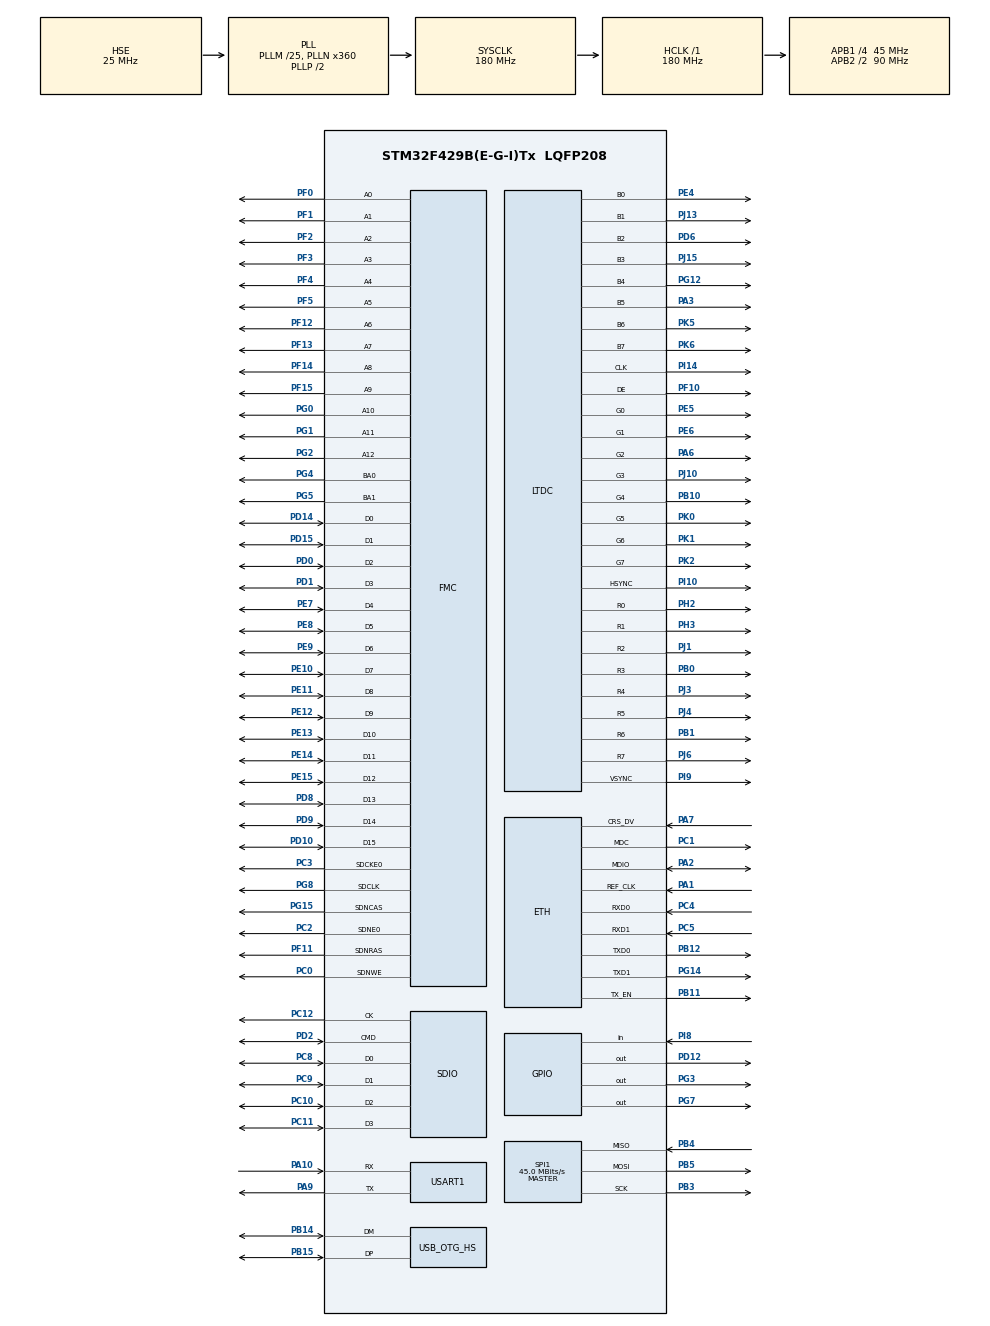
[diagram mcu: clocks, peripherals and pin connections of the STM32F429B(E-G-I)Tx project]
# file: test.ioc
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ETH.MediaInterface=ETH_MEDIA_INTERFACE_RMII
Mcu.Family=STM32F4
Mcu.Name=STM32F429B(E-G-I)Tx
Mcu.Package=LQFP208
NVIC.ETH_IRQn=true\:0\:0\:false\:false\:true
NVIC.PriorityGroup=NVIC_PRIORITYGROUP_2
NVIC.USART1_IRQn=true\:2\:1\:true\:true\:true\:1
PA1.Mode=RMII
PA1.Signal=ETH_REF_CLK
PA10.Mode=Asynchronous
PA10.Signal=USART1_RX
PA2.Mode=RMII
PA2.Signal=ETH_MDIO
PA3.Mode=RGB888
PA3.Signal=LTDC_B5
PA6.Mode=RGB888
PA6.Signal=LTDC_G2
PA7.Mode=RMII
PA7.Signal=ETH_CRS_DV
PA9.Mode=Asynchronous
PA9.Signal=USART1_TX
PB0.Mode=RGB888
PB0.Signal=LTDC_R3
PB1.Mode=RGB888
PB1.Signal=LTDC_R6
PB10.Mode=RGB888
PB10.Signal=LTDC_G4
PB11.Mode=RMII
PB11.Signal=ETH_TX_EN
PB12.Mode=RMII
PB12.Signal=ETH_TXD0
PB14.Mode=Device_Only_FS
PB14.Signal=USB_OTG_HS_DM
PB15.Mode=Device_Only_FS
PB15.Signal=USB_OTG_HS_DP
PB3.Mode=Full_Duplex_Master
PB3.Signal=SPI1_SCK
PB4.Mode=Full_Duplex_Master
PB4.Signal=SPI1_MISO
PB5.Mode=Full_Duplex_Master
PB5.Signal=SPI1_MOSI
PC0.Signal=FMC_SDNWE
PC1.Mode=RMII
PC1.Signal=ETH_MDC
PC10.Mode=SD_4_bits_Wide_bus
PC10.Signal=SDIO_D2
PC11.Mode=SD_4_bits_Wide_bus
PC11.Signal=SDIO_D3
PC12.Mode=SD_4_bits_Wide_bus
PC12.Signal=SDIO_CK
PC2.Mode=SdramChipSelect1_1
PC2.Signal=FMC_SDNE0
PC3.Mode=SdramChipSelect1_1
PC3.Signal=FMC_SDCKE0
PC4.Mode=RMII
PC4.Signal=ETH_RXD0
PC5.Mode=RMII
PC5.Signal=ETH_RXD1
PC8.Mode=SD_4_bits_Wide_bus
PC8.Signal=SDIO_D0
PC9.Mode=SD_4_bits_Wide_bus
PC9.Signal=SDIO_D1
PD0.Signal=FMC_D2_DA2
PD1.Signal=FMC_D3_DA3
PD10.Signal=FMC_D15_DA15
PD12.Signal=GPIO_Output
PD14.Signal=FMC_D0_DA0
PD15.Signal=FMC_D1_DA1
PD2.Mode=SD_4_bits_Wide_bus
PD2.Signal=SDIO_CMD
PD6.Mode=RGB888
PD6.Signal=LTDC_B2
PD8.Signal=FMC_D13_DA13
PD9.Signal=FMC_D14_DA14
PE10.Signal=FMC_D7_DA7
PE11.Signal=FMC_D8_DA8
PE12.Signal=FMC_D9_DA9
PE13.Signal=FMC_D10_DA10
PE14.Signal=FMC_D11_DA11
PE15.Signal=FMC_D12_DA12
PE4.Mode=RGB888
PE4.Signal=LTDC_B0
PE5.Mode=RGB888
PE5.Signal=LTDC_G0
PE6.Mode=RGB888
PE6.Signal=LTDC_G1
PE7.Signal=FMC_D4_DA4
PE8.Signal=FMC_D5_DA5
PE9.Signal=FMC_D6_DA6
PF0.Signal=FMC_A0
PF1.Signal=FMC_A1
PF10.Mode=RGB888
PF10.Signal=LTDC_DE
PF11.Signal=FMC_SDNRAS
PF12.Signal=FMC_A6
PF13.Signal=FMC_A7
PF14.Signal=FMC_A8
PF15.Signal=FMC_A9
PF2.Signal=FMC_A2
PF3.Signal=FMC_A3
PF4.Signal=FMC_A4
PF5.Signal=FMC_A5
PG0.Signal=FMC_A10
PG1.Signal=FMC_A11
PG12.Mode=RGB888
PG12.Signal=LTDC_B4
PG14.Mode=RMII
PG14.Signal=ETH_TXD1
PG15.Signal=FMC_SDNCAS
PG2.Signal=FMC_A12
PG3.Signal=GPIO_Output
PG4.Signal=FMC_A14_BA0
PG5.Signal=FMC_A15_BA1
PG7.Signal=GPIO_Output
PG8.Signal=FMC_SDCLK
PH0/OSC_IN.Mode=HSE-External-Oscillator
PH0/OSC_IN.Signal=RCC_OSC_IN
PH1/OSC_OUT.Mode=HSE-External-Oscillator
PH1/OSC_OUT.Signal=RCC_OSC_OUT
PH2.Mode=RGB888
PH2.Signal=LTDC_R0
PH3.Mode=RGB888
PH3.Signal=LTDC_R1
PI10.Mode=RGB888
PI10.Signal=LTDC_HSYNC
PI14.Mode=RGB888
PI14.Signal=LTDC_CLK
PI8.Signal=GPIO_Input
PI9.Mode=RGB888
PI9.Signal=LTDC_VSYNC
PJ1.Mode=RGB888
PJ1.Signal=LTDC_R2
PJ10.Mode=RGB888
PJ10.Signal=LTDC_G3
PJ13.Mode=RGB888
PJ13.Signal=LTDC_B1
PJ15.Mode=RGB888
PJ15.Signal=LTDC_B3
PJ3.Mode=RGB888
PJ3.Signal=LTDC_R4
PJ4.Mode=RGB888
PJ4.Signal=LTDC_R5
PJ6.Mode=RGB888
PJ6.Signal=LTDC_R7
PK0.Mode=RGB888
PK0.Signal=LTDC_G5
PK1.Mode=RGB888
PK1.Signal=LTDC_G6
PK2.Mode=RGB888
PK2.Signal=LTDC_G7
PK5.Mode=RGB888
PK5.Signal=LTDC_B6
PK6.Mode=RGB888
PK6.Signal=LTDC_B7
ProjectManager.HeapSize=0x200
ProjectManager.StackSize=0x400
ProjectManager.TargetToolchain=MDK-ARM V5
RCC.48MHZClocksFreq_Value=90000000
RCC.AHBFreq_Value=180000000
RCC.APB1CLKDivider=RCC_HCLK_DIV4
RCC.APB1Freq_Value=45000000
RCC.APB1TimFreq_Value=90000000
RCC.APB2CLKDivider=RCC_HCLK_DIV2
RCC.APB2Freq_Value=90000000
RCC.APB2TimFreq_Value=180000000
RCC.CortexFreq_Value=180000000
RCC.HCLKFreq_Value=180000000
RCC.HSE_VALUE=25000000
RCC.HSI_VALUE=16000000
RCC.LSE_VALUE=32768
RCC.PLLM=25
RCC.PLLN=360
RCC.PLLSAIN=100
RCC.SYSCLKFreq_VALUE=180000000
RCC.SYSCLKSource=RCC_SYSCLKSOURCE_PLLCLK
RCC.VCOOutputFreq_Value=360000000
SH.FMC_A0.0=FMC_A0,13b-sda1
SH.FMC_A1.0=FMC_A1,13b-sda1
SH.FMC_A10.0=FMC_A10,13b-sda1
SH.FMC_A11.0=FMC_A11,13b-sda1
SH.FMC_A12.0=FMC_A12,13b-sda1
SH.FMC_A14_BA0.0=FMC_BA0,FourSdramBanks1
SH.FMC_A15_BA1.0=FMC_BA1,FourSdramBanks1
SH.FMC_A2.0=FMC_A2,13b-sda1
SH.FMC_A3.0=FMC_A3,13b-sda1
SH.FMC_A4.0=FMC_A4,13b-sda1
SH.FMC_A5.0=FMC_A5,13b-sda1
SH.FMC_A6.0=FMC_A6,13b-sda1
SH.FMC_A7.0=FMC_A7,13b-sda1
SH.FMC_A8.0=FMC_A8,13b-sda1
SH.FMC_A9.0=FMC_A9,13b-sda1
SH.FMC_D0_DA0.0=FMC_D0,sd-16b-d1
SH.FMC_D10_DA10.0=FMC_D10,sd-16b-d1
SH.FMC_D11_DA11.0=FMC_D11,sd-16b-d1
SH.FMC_D12_DA12.0=FMC_D12,sd-16b-d1
SH.FMC_D13_DA13.0=FMC_D13,sd-16b-d1
SH.FMC_D14_DA14.0=FMC_D14,sd-16b-d1
SH.FMC_D15_DA15.0=FMC_D15,sd-16b-d1
SH.FMC_D1_DA1.0=FMC_D1,sd-16b-d1
SH.FMC_D2_DA2.0=FMC_D2,sd-16b-d1
SH.FMC_D3_DA3.0=FMC_D3,sd-16b-d1
SH.FMC_D4_DA4.0=FMC_D4,sd-16b-d1
SH.FMC_D5_DA5.0=FMC_D5,sd-16b-d1
SH.FMC_D6_DA6.0=FMC_D6,sd-16b-d1
SH.FMC_D7_DA7.0=FMC_D7,sd-16b-d1
SH.FMC_D8_DA8.0=FMC_D8,sd-16b-d1
SH.FMC_D9_DA9.0=FMC_D9,sd-16b-d1
SH.FMC_SDCLK.0=FMC_SDCLK,13b-sda1
SH.FMC_SDNCAS.0=FMC_SDNCAS,13b-sda1
SH.FMC_SDNRAS.0=FMC_SDNRAS,13b-sda1
SH.FMC_SDNWE.0=FMC_SDNWE,13b-sda1
SPI1.BaudRatePrescaler=SPI_BAUDRATEPRESCALER_2
SPI1.CalculateBaudRate=45.0 MBits/s
SPI1.Direction=SPI_DIRECTION_2LINES
SPI1.Mode=SPI_MODE_MASTER
SPI1.VirtualType=VM_MASTER
USART1.VirtualMode=VM_ASYNC
USB_OTG_HS.VirtualMode-Device_Only_FS=Device_Only_FS
board=test

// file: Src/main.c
/**
  ******************************************************************************
  * File Name          : main.c
  * Description        : Main program body
  ******************************************************************************
  ** This notice applies to any and all portions of this file
  * that are not between comment pairs USER CODE BEGIN and
  * USER CODE END. Other portions of this file, whether
  * inserted by the user or by software development tools
  * are owned by their respective copyright owners.
  *
  * COPYRIGHT(c) 2017 STMicroelectronics
  *
  * Redistribution and use in source and binary forms, with or without modification,
  * are permitted provided that the following conditions are met:
  *   1. Redistributions of source code must retain the above copyright notice,
  *      this list of conditions and the following disclaimer.
  *   2. Redistributions in binary form must reproduce the above copyright notice,
  *      this list of conditions and the following disclaimer in the documentation
  *      and/or other materials provided with the distribution.
  *   3. Neither the name of STMicroelectronics nor the names of its contributors
  *      may be used to endorse or promote products derived from this software
  *      without specific prior written permission.
  *
  * THIS SOFTWARE IS PROVIDED BY THE COPYRIGHT HOLDERS AND CONTRIBUTORS "AS IS"
  * AND ANY EXPRESS OR IMPLIED WARRANTIES, INCLUDING, BUT NOT LIMITED TO, THE
  * IMPLIED WARRANTIES OF MERCHANTABILITY AND FITNESS FOR A PARTICULAR PURPOSE ARE
  * DISCLAIMED. IN NO EVENT SHALL THE COPYRIGHT HOLDER OR CONTRIBUTORS BE LIABLE
  * FOR ANY DIRECT, INDIRECT, INCIDENTAL, SPECIAL, EXEMPLARY, OR CONSEQUENTIAL
  * DAMAGES (INCLUDING, BUT NOT LIMITED TO, PROCUREMENT OF SUBSTITUTE GOODS OR
  * SERVICES; LOSS OF USE, DATA, OR PROFITS; OR BUSINESS INTERRUPTION) HOWEVER
  * CAUSED AND ON ANY THEORY OF LIABILITY, WHETHER IN CONTRACT, STRICT LIABILITY,
  * OR TORT (INCLUDING NEGLIGENCE OR OTHERWISE) ARISING IN ANY WAY OUT OF THE USE
  * OF THIS SOFTWARE, EVEN IF ADVISED OF THE POSSIBILITY OF SUCH DAMAGE.
  *
  ******************************************************************************
  */
#include "main.h"
#include "string.h"
#include "stm32f4xx_hal.h"

ETH_HandleTypeDef heth;

LTDC_HandleTypeDef hltdc;

SD_HandleTypeDef hsd;

SPI_HandleTypeDef hspi1;

UART_HandleTypeDef huart1;

PCD_HandleTypeDef hpcd_USB_OTG_HS;

SDRAM_HandleTypeDef hsdram1;

/* USER CODE BEGIN PV */
/* Private variables ---------------------------------------------------------*/

/* USER CODE END PV */

void SystemClock_Config(void);
static void MX_GPIO_Init(void);
static void MX_FMC_Init(void);
static void MX_LTDC_Init(void);
static void MX_SDIO_SD_Init(void);
static void MX_SPI1_Init(void);
static void MX_USB_OTG_HS_PCD_Init(void);
static void MX_ETH_Init(void);
static void MX_USART1_UART_Init(void);
static void MX_NVIC_Init(void);

/* USER CODE BEGIN PFP */
/* Private function prototypes -----------------------------------------------*/

/* USER CODE END PFP */

/* USER CODE BEGIN 0 */

uint32_t t = 0;
uint8_t Rx[200];
uint8_t Tx[200];
//D17 G7
void LED_Func()
{
	HAL_GPIO_TogglePin(GPIOD,GPIO_PIN_12);
	HAL_GPIO_TogglePin(GPIOG,GPIO_PIN_7);
}

void delay(uint32_t d)
{
	while(d--);
}
//-----------------------------------------------------
typedef struct
{
	uint8_t Read;
	uint8_t Write;
	uint8_t Lenth;
	uint8_t Data[256];
}RING;
RING TX,RX;

void Buffer_Init(void )
{
	memset(&RX,0,sizeof(RING));
	memset(&TX,0,sizeof(RING));
}
void Write_Data(RING *ring,uint8_t data)
{
	ring->Data[ring->Write] = data;
	ring->Write++;
	ring->Lenth++;
}
uint8_t Read_Data(RING *ring)
{
	if(ring->Lenth)
		ring->Lenth--;
	return ring->Data[ring->Read++];
}

void HAL_UART_RxCpltCallback(UART_HandleTypeDef *huart)
{
	HAL_UART_Receive_IT(&huart1, Rx, 1);
	if(RX.Lenth<255)
		Write_Data(&RX,Rx[0]);
}

void HAL_UART_TxCpltCallback(UART_HandleTypeDef *huart)
{
	uint8_t temp;
	if (RX.Lenth)
	{
		temp = Read_Data(&RX);
		while(HAL_OK != HAL_UART_Transmit_IT(huart,&temp,1));
	}
}
//-----------------------------------------------------
/* USER CODE END 0 */

int main(void)
{

  /* USER CODE BEGIN 1 */
		uint8_t temp;
  /* USER CODE END 1 */

  /* MCU Configuration----------------------------------------------------------*/

  /* Reset of all peripherals, Initializes the Flash interface and the Systick. */
  HAL_Init();

  /* Configure the system clock */
  SystemClock_Config();

  /* Initialize all configured peripherals */
  MX_GPIO_Init();
  MX_FMC_Init();
  MX_LTDC_Init();
  MX_SDIO_SD_Init();
  MX_SPI1_Init();
  MX_USB_OTG_HS_PCD_Init();
  MX_ETH_Init();
  MX_USART1_UART_Init();

  /* Initialize interrupts */
  MX_NVIC_Init();

	memcpy(Tx,"USART TEST\r\n",18);
	HAL_UART_Transmit_IT(&huart1, Tx, sizeof(Tx));

	HAL_UART_Receive_IT(&huart1, Rx, 1);
  /* Infinite loop */
  while (1)
  {

	if (RX.Lenth)//有接收到数据，开启发送中断
	{
		temp = Read_Data(&RX);
		while(HAL_OK != HAL_UART_Transmit_IT(&huart1,&temp,1));
	}
	delay(3000000);
  }

}

/** System Clock Configuration
*/
void SystemClock_Config(void)
{

  RCC_OscInitTypeDef RCC_OscInitStruct;
  RCC_ClkInitTypeDef RCC_ClkInitStruct;
  RCC_PeriphCLKInitTypeDef PeriphClkInitStruct;

    /**Configure the main internal regulator output voltage
    */
  __HAL_RCC_PWR_CLK_ENABLE();

  __HAL_PWR_VOLTAGESCALING_CONFIG(PWR_REGULATOR_VOLTAGE_SCALE1);

    /**Initializes the CPU, AHB and APB busses clocks
    */
  RCC_OscInitStruct.OscillatorType = RCC_OSCILLATORTYPE_HSE;
  RCC_OscInitStruct.HSEState = RCC_HSE_ON;
  RCC_OscInitStruct.PLL.PLLState = RCC_PLL_ON;
  RCC_OscInitStruct.PLL.PLLSource = RCC_PLLSOURCE_HSE;
  RCC_OscInitStruct.PLL.PLLM = 25;
  RCC_OscInitStruct.PLL.PLLN = 360;
  RCC_OscInitStruct.PLL.PLLP = RCC_PLLP_DIV2;
  RCC_OscInitStruct.PLL.PLLQ = 4;
  if (HAL_RCC_OscConfig(&RCC_OscInitStruct) != HAL_OK)
  {
    _Error_Handler(__FILE__, __LINE__);
  }

    /**Activate the Over-Drive mode
    */
  if (HAL_PWREx_EnableOverDrive() != HAL_OK)
  {
    _Error_Handler(__FILE__, __LINE__);
  }

    /**Initializes the CPU, AHB and APB busses clocks
    */
  RCC_ClkInitStruct.ClockType = RCC_CLOCKTYPE_HCLK|RCC_CLOCKTYPE_SYSCLK
                              |RCC_CLOCKTYPE_PCLK1|RCC_CLOCKTYPE_PCLK2;
  RCC_ClkInitStruct.SYSCLKSource = RCC_SYSCLKSOURCE_PLLCLK;
  RCC_ClkInitStruct.AHBCLKDivider = RCC_SYSCLK_DIV1;
  RCC_ClkInitStruct.APB1CLKDivider = RCC_HCLK_DIV4;
  RCC_ClkInitStruct.APB2CLKDivider = RCC_HCLK_DIV2;

  if (HAL_RCC_ClockConfig(&RCC_ClkInitStruct, FLASH_LATENCY_5) != HAL_OK)
  {
    _Error_Handler(__FILE__, __LINE__);
  }

  PeriphClkInitStruct.PeriphClockSelection = RCC_PERIPHCLK_LTDC;
  PeriphClkInitStruct.PLLSAI.PLLSAIN = 100;
  PeriphClkInitStruct.PLLSAI.PLLSAIR = 2;
  PeriphClkInitStruct.PLLSAIDivR = RCC_PLLSAIDIVR_2;
  if (HAL_RCCEx_PeriphCLKConfig(&PeriphClkInitStruct) != HAL_OK)
  {
    _Error_Handler(__FILE__, __LINE__);
  }

    /**Configure the Systick interrupt time
    */
  HAL_SYSTICK_Config(HAL_RCC_GetHCLKFreq()/1000);

    /**Configure the Systick
    */
  HAL_SYSTICK_CLKSourceConfig(SYSTICK_CLKSOURCE_HCLK);

  /* SysTick_IRQn interrupt configuration */
  HAL_NVIC_SetPriority(SysTick_IRQn, 0, 0);
}

/** NVIC Configuration
*/
static void MX_NVIC_Init(void)
{
  /* USART1_IRQn interrupt configuration */
  HAL_NVIC_SetPriority(USART1_IRQn, 2, 1);
  HAL_NVIC_EnableIRQ(USART1_IRQn);
}

/* ETH init function */
static void MX_ETH_Init(void)
{

   uint8_t MACAddr[6] ;

  heth.Instance = ETH;
  heth.Init.AutoNegotiation = ETH_AUTONEGOTIATION_ENABLE;
  heth.Init.PhyAddress = LAN8742A_PHY_ADDRESS;
  MACAddr[0] = 0x00;
  MACAddr[1] = 0x80;
  MACAddr[2] = 0xE1;
  MACAddr[3] = 0x00;
  MACAddr[4] = 0x00;
  MACAddr[5] = 0x00;
  heth.Init.MACAddr = &MACAddr[0];
  heth.Init.RxMode = ETH_RXPOLLING_MODE;
  heth.Init.ChecksumMode = ETH_CHECKSUM_BY_HARDWARE;
  heth.Init.MediaInterface = ETH_MEDIA_INTERFACE_RMII;

  if (HAL_ETH_Init(&heth) != HAL_OK)
  {
    _Error_Handler(__FILE__, __LINE__);
  }

}

/* LTDC init function */
static void MX_LTDC_Init(void)
{

  LTDC_LayerCfgTypeDef pLayerCfg;
  LTDC_LayerCfgTypeDef pLayerCfg1;

  hltdc.Instance = LTDC;
  hltdc.Init.HSPolarity = LTDC_HSPOLARITY_AL;
  hltdc.Init.VSPolarity = LTDC_VSPOLARITY_AL;
  hltdc.Init.DEPolarity = LTDC_DEPOLARITY_AL;
  hltdc.Init.PCPolarity = LTDC_PCPOLARITY_IPC;
  hltdc.Init.HorizontalSync = 7;
  hltdc.Init.VerticalSync = 3;
  hltdc.Init.AccumulatedHBP = 14;
  hltdc.Init.AccumulatedVBP = 5;
  hltdc.Init.AccumulatedActiveW = 654;
  hltdc.Init.AccumulatedActiveH = 485;
  hltdc.Init.TotalWidth = 660;
  hltdc.Init.TotalHeigh = 487;
  hltdc.Init.Backcolor.Blue = 0;
  hltdc.Init.Backcolor.Green = 0;
  hltdc.Init.Backcolor.Red = 0;
  if (HAL_LTDC_Init(&hltdc) != HAL_OK)
  {
    _Error_Handler(__FILE__, __LINE__);
  }

  pLayerCfg.WindowX0 = 0;
  pLayerCfg.WindowX1 = 0;
  pLayerCfg.WindowY0 = 0;
  pLayerCfg.WindowY1 = 0;
  pLayerCfg.PixelFormat = LTDC_PIXEL_FORMAT_ARGB8888;
  pLayerCfg.Alpha = 0;
  pLayerCfg.Alpha0 = 0;
  pLayerCfg.BlendingFactor1 = LTDC_BLENDING_FACTOR1_CA;
  pLayerCfg.BlendingFactor2 = LTDC_BLENDING_FACTOR2_CA;
  pLayerCfg.FBStartAdress = 0;
  pLayerCfg.ImageWidth = 0;
  pLayerCfg.ImageHeight = 0;
  pLayerCfg.Backcolor.Blue = 0;
  pLayerCfg.Backcolor.Green = 0;
  pLayerCfg.Backcolor.Red = 0;
  if (HAL_LTDC_ConfigLayer(&hltdc, &pLayerCfg, 0) != HAL_OK)
  {
    _Error_Handler(__FILE__, __LINE__);
  }

  pLayerCfg1.WindowX0 = 0;
  pLayerCfg1.WindowX1 = 0;
  pLayerCfg1.WindowY0 = 0;
  pLayerCfg1.WindowY1 = 0;
  pLayerCfg1.PixelFormat = LTDC_PIXEL_FORMAT_ARGB8888;
  pLayerCfg1.Alpha = 0;
  pLayerCfg1.Alpha0 = 0;
  pLayerCfg1.BlendingFactor1 = LTDC_BLENDING_FACTOR1_CA;
  pLayerCfg1.BlendingFactor2 = LTDC_BLENDING_FACTOR2_CA;
  pLayerCfg1.FBStartAdress = 0;
  pLayerCfg1.ImageWidth = 0;
  pLayerCfg1.ImageHeight = 0;
  pLayerCfg1.Backcolor.Blue = 0;
  pLayerCfg1.Backcolor.Green = 0;
  pLayerCfg1.Backcolor.Red = 0;
  if (HAL_LTDC_ConfigLayer(&hltdc, &pLayerCfg1, 1) != HAL_OK)
  {
    _Error_Handler(__FILE__, __LINE__);
  }

}

/* SDIO init function */
static void MX_SDIO_SD_Init(void)
{

  hsd.Instance = SDIO;
  hsd.Init.ClockEdge = SDIO_CLOCK_EDGE_RISING;
  hsd.Init.ClockBypass = SDIO_CLOCK_BYPASS_DISABLE;
  hsd.Init.ClockPowerSave = SDIO_CLOCK_POWER_SAVE_DISABLE;
  hsd.Init.BusWide = SDIO_BUS_WIDE_1B;
  hsd.Init.HardwareFlowControl = SDIO_HARDWARE_FLOW_CONTROL_DISABLE;
  hsd.Init.ClockDiv = 0;
  if (HAL_SD_Init(&hsd) != HAL_OK)
  {
    _Error_Handler(__FILE__, __LINE__);
  }

  HAL_SD_ConfigWideBusOperation(&hsd, SDIO_BUS_WIDE_4B);

}

/* SPI1 init function */
static void MX_SPI1_Init(void)
{

  hspi1.Instance = SPI1;
  hspi1.Init.Mode = SPI_MODE_MASTER;
  hspi1.Init.Direction = SPI_DIRECTION_2LINES;
  hspi1.Init.DataSize = SPI_DATASIZE_8BIT;
  hspi1.Init.CLKPolarity = SPI_POLARITY_LOW;
  hspi1.Init.CLKPhase = SPI_PHASE_1EDGE;
  hspi1.Init.NSS = SPI_NSS_SOFT;
  hspi1.Init.BaudRatePrescaler = SPI_BAUDRATEPRESCALER_2;
  hspi1.Init.FirstBit = SPI_FIRSTBIT_MSB;
  hspi1.Init.TIMode = SPI_TIMODE_DISABLE;
  hspi1.Init.CRCCalculation = SPI_CRCCALCULATION_DISABLE;
  hspi1.Init.CRCPolynomial = 10;
  if (HAL_SPI_Init(&hspi1) != HAL_OK)
  {
    _Error_Handler(__FILE__, __LINE__);
  }

}

/* USART1 init function */
static void MX_USART1_UART_Init(void)
{

  huart1.Instance = USART1;
  huart1.Init.BaudRate = 115200;
  huart1.Init.WordLength = UART_WORDLENGTH_8B;
  huart1.Init.StopBits = UART_STOPBITS_1;
  huart1.Init.Parity = UART_PARITY_NONE;
  huart1.Init.Mode = UART_MODE_TX_RX;
  huart1.Init.HwFlowCtl = UART_HWCONTROL_NONE;
  huart1.Init.OverSampling = UART_OVERSAMPLING_16;
  if (HAL_UART_Init(&huart1) != HAL_OK)
  {
    _Error_Handler(__FILE__, __LINE__);
  }

}

/* USB_OTG_HS init function */
static void MX_USB_OTG_HS_PCD_Init(void)
{

  hpcd_USB_OTG_HS.Instance = USB_OTG_HS;
  hpcd_USB_OTG_HS.Init.dev_endpoints = 6;
  hpcd_USB_OTG_HS.Init.speed = PCD_SPEED_FULL;
  hpcd_USB_OTG_HS.Init.dma_enable = DISABLE;
  hpcd_USB_OTG_HS.Init.ep0_mps = DEP0CTL_MPS_64;
  hpcd_USB_OTG_HS.Init.phy_itface = USB_OTG_EMBEDDED_PHY;
  hpcd_USB_OTG_HS.Init.Sof_enable = DISABLE;
  hpcd_USB_OTG_HS.Init.low_power_enable = DISABLE;
  hpcd_USB_OTG_HS.Init.lpm_enable = DISABLE;
  hpcd_USB_OTG_HS.Init.vbus_sensing_enable = DISABLE;
  hpcd_USB_OTG_HS.Init.use_dedicated_ep1 = DISABLE;
  hpcd_USB_OTG_HS.Init.use_external_vbus = DISABLE;
  if (HAL_PCD_Init(&hpcd_USB_OTG_HS) != HAL_OK)
  {
    _Error_Handler(__FILE__, __LINE__);
  }

}
/* FMC initialization function */
static void MX_FMC_Init(void)
{
  FMC_SDRAM_TimingTypeDef SdramTiming;

  /** Perform the SDRAM1 memory initialization sequence
  */
  hsdram1.Instance = FMC_SDRAM_DEVICE;
  /* hsdram1.Init */
  hsdram1.Init.SDBank = FMC_SDRAM_BANK1;
  hsdram1.Init.ColumnBitsNumber = FMC_SDRAM_COLUMN_BITS_NUM_8;
  hsdram1.Init.RowBitsNumber = FMC_SDRAM_ROW_BITS_NUM_13;
  hsdram1.Init.MemoryDataWidth = FMC_SDRAM_MEM_BUS_WIDTH_16;
  hsdram1.Init.InternalBankNumber = FMC_SDRAM_INTERN_BANKS_NUM_4;
  hsdram1.Init.CASLatency = FMC_SDRAM_CAS_LATENCY_1;
  hsdram1.Init.WriteProtection = FMC_SDRAM_WRITE_PROTECTION_DISABLE;
  hsdram1.Init.SDClockPeriod = FMC_SDRAM_CLOCK_DISABLE;
  hsdram1.Init.ReadBurst = FMC_SDRAM_RBURST_DISABLE;
  hsdram1.Init.ReadPipeDelay = FMC_SDRAM_RPIPE_DELAY_0;
  /* SdramTiming */
  SdramTiming.LoadToActiveDelay = 16;
  SdramTiming.ExitSelfRefreshDelay = 16;
  SdramTiming.SelfRefreshTime = 16;
  SdramTiming.RowCycleDelay = 16;
  SdramTiming.WriteRecoveryTime = 16;
  SdramTiming.RPDelay = 16;
  SdramTiming.RCDDelay = 16;

  if (HAL_SDRAM_Init(&hsdram1, &SdramTiming) != HAL_OK)
  {
    _Error_Handler(__FILE__, __LINE__);
  }

}

/** Configure pins as
        * Analog
        * Input
        * Output
        * EVENT_OUT
        * EXTI
*/
static void MX_GPIO_Init(void)
{

  GPIO_InitTypeDef GPIO_InitStruct;

  /* GPIO Ports Clock Enable */
  __HAL_RCC_GPIOE_CLK_ENABLE();
  __HAL_RCC_GPIOI_CLK_ENABLE();
  __HAL_RCC_GPIOF_CLK_ENABLE();
  __HAL_RCC_GPIOH_CLK_ENABLE();
  __HAL_RCC_GPIOC_CLK_ENABLE();
  __HAL_RCC_GPIOA_CLK_ENABLE();
  __HAL_RCC_GPIOB_CLK_ENABLE();
  __HAL_RCC_GPIOJ_CLK_ENABLE();
  __HAL_RCC_GPIOG_CLK_ENABLE();
  __HAL_RCC_GPIOD_CLK_ENABLE();
  __HAL_RCC_GPIOK_CLK_ENABLE();

  /*Configure GPIO pin Output Level */
  HAL_GPIO_WritePin(GPIOD, GPIO_PIN_12, GPIO_PIN_RESET);

  /*Configure GPIO pin Output Level */
  HAL_GPIO_WritePin(GPIOG, GPIO_PIN_3|GPIO_PIN_7, GPIO_PIN_RESET);

  /*Configure GPIO pin : PI8 */
  GPIO_InitStruct.Pin = GPIO_PIN_8;
  GPIO_InitStruct.Mode = GPIO_MODE_INPUT;
  GPIO_InitStruct.Pull = GPIO_NOPULL;
  HAL_GPIO_Init(GPIOI, &GPIO_InitStruct);

  /*Configure GPIO pin : PD12 */
  GPIO_InitStruct.Pin = GPIO_PIN_12;
  GPIO_InitStruct.Mode = GPIO_MODE_OUTPUT_PP;
  GPIO_InitStruct.Pull = GPIO_NOPULL;
  GPIO_InitStruct.Speed = GPIO_SPEED_FREQ_LOW;
  HAL_GPIO_Init(GPIOD, &GPIO_InitStruct);

  /*Configure GPIO pins : PG3 PG7 */
  GPIO_InitStruct.Pin = GPIO_PIN_3|GPIO_PIN_7;
  GPIO_InitStruct.Mode = GPIO_MODE_OUTPUT_PP;
  GPIO_InitStruct.Pull = GPIO_NOPULL;
  GPIO_InitStruct.Speed = GPIO_SPEED_FREQ_LOW;
  HAL_GPIO_Init(GPIOG, &GPIO_InitStruct);

}

void _Error_Handler(char * file, int line)
{
  while(1)
  {
  }
}

/************************ (C) COPYRIGHT STMicroelectronics *****END OF FILE****/
